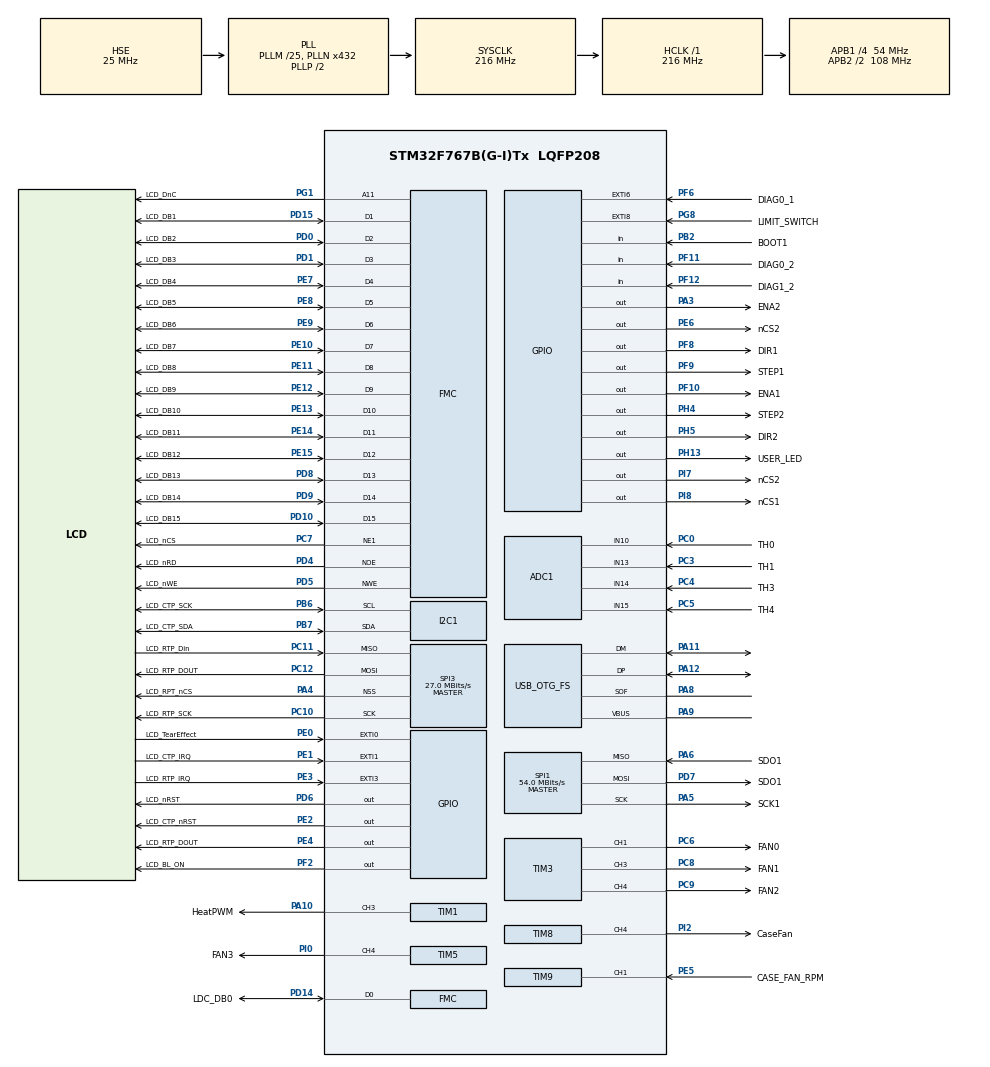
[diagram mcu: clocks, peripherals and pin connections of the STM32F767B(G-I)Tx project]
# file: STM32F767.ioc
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PD7.Mode=Full_Duplex_Master
SH.FMC_D7_DA7.0=FMC_D7,16b-d1
VP_TIM5_VS_ClockSourceINT.Mode=Internal
SPI3.Direction=SPI_DIRECTION_2LINES
SPI3.VirtualType=VM_MASTER
SPI1.VirtualType=VM_MASTER
VP_ADC1_TempSens_Input.Mode=IN-TempSens
PG8.Signal=GPXTI8
PC12.Signal=SPI3_MOSI
PC6.GPIO_Label=FAN0
VP_RTC_VS_RTC_Activate.Mode=RTC_Enabled
PA6.GPIO_Label=SDO1
PB6.GPIO_Label=LCD_CTP_SCK
TIM8.Channel-PWM\ Generation4\ CH4=TIM_CHANNEL_4
SH.FMC_D5_DA5.0=FMC_D5,16b-d1
PD6.GPIO_Label=LCD_nRST
TIM3.Channel-PWM\ Generation4\ CH4=TIM_CHANNEL_4
PE6.GPIO_Label=nCS2
PF6.GPIO_Label=DIAG0_1
SH.FMC_NWE.0=FMC_NWE,Lcd1
RCC.SYSCLKSource=RCC_SYSCLKSOURCE_PLLCLK
SH.FMC_D9_DA9.0=FMC_D9,16b-d1
FREERTOS.configENABLE_FPU=1
PH5.Signal=GPIO_Output
PA4.Mode=NSS_Signal_Hard_Output
NVIC.DMA2D_IRQn=true\:5\:0\:false\:false\:true\:true\:true\:true
SPI1.Direction=SPI_DIRECTION_2LINES
SPI3.VirtualNSS=VM_NSSHARD
SH.FMC_D11_DA11.0=FMC_D11,16b-d1
PD4.Signal=FMC_NOE
RCC.APB2TimFreq_Value=216000000
PB6.Signal=I2C1_SCL
PC7.Signal=FMC_NE1
PH1/OSC_OUT.Signal=RCC_OSC_OUT
PB6.Mode=I2C
SPI1.CalculateBaudRate=54.0 MBits/s
PC3.Signal=ADCx_IN13
PD0.Signal=FMC_D2_DA2
PD8.Signal=FMC_D13_DA13
PE5.Signal=S_TIM9_CH1
PE1.Signal=GPXTI1
FREERTOS.configMINIMAL_STACK_SIZE=2048
PF10.GPIO_Label=ENA1
PB2.Signal=GPIO_Input
SH.ADCx_IN15.0=ADC1_IN15,IN15
PD1.GPIO_Label=LCD_DB3
PF12.GPIO_Label=DIAG1_2
FMC.DataSetupTime1=8
PC4.GPIO_Label=TH3
PE9.Signal=FMC_D6_DA6
PF6.Stacked=true
PE4.GPIO_Label=LCD_RTP_DOUT
PE2.Signal=GPIO_Output
PA8.Signal=USB_OTG_FS_SOF
SH.FMC_D1_DA1.0=FMC_D1,16b-d1
PE10.Signal=FMC_D7_DA7
VP_TIM1_VS_ClockSourceINT.Mode=Internal
ADC1.SamplingTime-0\#ChannelRegularConversion=ADC_SAMPLETIME_3CYCLES
Mcu.Package=LQFP208
FREERTOS.configUSE_NEWLIB_REENTRANT=1
SH.S_TIM8_CH4.0=TIM8_CH4,PWM Generation4 CH4
NVIC.TimeBase=TIM7_IRQn
SPI3.Mode=SPI_MODE_MASTER
SH.ADCx_IN14.0=ADC1_IN14,IN14
STMicroelectronics.X-CUBE-TOUCHGFX.4.16.1.ApplicationCcGraphicsJjApplication=TouchGFXOoGenerator
NVIC.TimeBaseIP=TIM7
PA10.Signal=S_TIM1_CH3
VP_RTC_VS_RTC_Calendar.Mode=RTC_Calendar
PE12.GPIO_Label=LCD_DB9
PC11.Mode=Full_Duplex_Master
RCC.APB2CLKDivider=RCC_HCLK_DIV2
RCC.APB1TimFreq_Value=108000000
VP_DMA2D_VS_DMA2D.Mode=DMA2D_Activate
PE10.GPIO_Label=LCD_DB7
PA4.GPIO_Label=LCD_RPT_nCS
PD15.Signal=FMC_D1_DA1
SH.FMC_D3_DA3.0=FMC_D3,16b-d1
STMicroelectronics.X-CUBE-TOUCHGFX.4.16.1.tgfx_block_size=16000
PA5.Mode=Full_Duplex_Master
VP_STMicroelectronics.X-CUBE-TOUCHGFX_VS_GraphicsJjApplication_4.16.1.Mode=GraphicsJjApplication
VP_TIM9_VS_ControllerModeClock.Mode=Clock Mode
STMicroelectronics.X-CUBE-TOUCHGFX.4.16.1.tgfx_custom_height=480
FREERTOS.Tasks01=defaultTask,24,2048,StartDefaultTask,Default,NULL,Dynamic,NULL,NULL
ADC1.Rank-0\#ChannelRegularConversion=1
PH13.Signal=GPIO_Output
PD9.GPIO_Label=LCD_DB14
FREERTOS.INCLUDE_xTaskGetCurrentTaskHandle=1
SH.FMC_D10_DA10.0=FMC_D10,16b-d1
PC6.Signal=S_TIM3_CH1
PD7.Signal=SPI1_MOSI
PD1.Signal=FMC_D3_DA3
VP_TIM8_VS_ClockSourceITR.Mode=TriggerSource_ITR0
PC0.Signal=ADCx_IN10
RCC.APB1CLKDivider=RCC_HCLK_DIV4
SH.FMC_NOE.0=FMC_NOE,Lcd1
PF8.GPIO_Label=DIR1
PD10.Signal=FMC_D15_DA15
TIM3.Channel-PWM\ Generation3\ CH3=TIM_CHANNEL_3
FMC.AddressSetupTime1=6
PI8.GPIO_Label=nCS1
USB_DEVICE.PRODUCT_STRING_CDC_FS=KTI-STM32 Virtual ComPort
SH.FMC_D15_DA15.0=FMC_D15,16b-d1
PE8.GPIO_Label=LCD_DB5
PA9.Signal=USB_OTG_FS_VBUS
I2C1.Timing=0x20404768
PE9.GPIO_Label=LCD_DB6
PA5.Signal=SPI1_SCK
PC12.Mode=Full_Duplex_Master
PE1.GPIO_Label=LCD_CTP_IRQ
PI7.Signal=GPIO_Output
PE14.Signal=FMC_D11_DA11
PE15.Signal=FMC_D12_DA12
PE8.Signal=FMC_D5_DA5
SPI1.Mode=SPI_MODE_MASTER
PI2.Signal=S_TIM8_CH4
SH.S_TIM9_CH1.0=TIM9_CH1,TriggerSource_TI1ED
PA13.Mode=Serial_Wire
VP_TIM9_VS_CH1.Mode=Input_Capture1_from_TRC
PC7.GPIO_Label=LCD_nCS
PA4.Signal=SPI3_NSS
ADC1.master=1
PE13.GPIO_Label=LCD_DB10
PA5.GPIO_Label=SCK1
PE5.GPIO_Label=CASE_FAN_RPM
PC12.GPIO_Label=LCD_RTP_DOUT
PA11.Signal=USB_OTG_FS_DM
ProjectManager.HeapSize=0x10000
PF9.Signal=GPIO_Output
NVIC.PriorityGroup=NVIC_PRIORITYGROUP_4
PE3.Signal=GPXTI3
PC3.GPIO_Label=TH1
PA8.Mode=Activate_SOF_FS
TIM1.Channel-PWM\ Generation3\ CH3=TIM_CHANNEL_3
VP_TIM8_VS_ControllerModeReset.Mode=Reset Mode
Mcu.Family=STM32F7
PA6.Mode=Full_Duplex_Master
USB_DEVICE.CLASS_NAME_FS=CDC
RCC.CortexFreq_Value=216000000
TIM5.Channel-Output\ Compare4\ CH4=TIM_CHANNEL_4
SH.FMC_D14_DA14.0=FMC_D14,16b-d1
PE11.GPIO_Label=LCD_DB8
STMicroelectronics.X-CUBE-TOUCHGFX.4.16.1.tgfx_buffering_strategy=Partial
PC10.Signal=SPI3_SCK
SH.FMC_D6_DA6.0=FMC_D6,16b-d1
PC0.GPIO_Label=TH0
PD0.GPIO_Label=LCD_DB2
PA11.Mode=Device_Only
STMicroelectronics.X-CUBE-ALGOBUILD.1.2.0.LibraryCcMotionOoLibrariesJjMotionOoLibraries=true
USB_DEVICE.VirtualMode-CDC_FS=Cdc
PH5.GPIO_Label=DIR2
SH.FMC_A11.0=FMC_A11,A11_1
ProjectManager.StackSize=0x1000
VP_FREERTOS_VS_CMSIS_V2.Mode=CMSIS_V2
TIM9.Channel-Input_Capture1_from_TRC=TIM_CHANNEL_1
PA12.Signal=USB_OTG_FS_DP
VP_STMicroelectronics.X-CUBE-ALGOBUILD_VS_MotionOoLibrariesJjLibrary_1.2.0_1.2.0.Mode=MotionOoLibrariesJjLibrary
PH0/OSC_IN.Mode=HSE-External-Clock-Source
RCC.HCLKFreq_Value=216000000
PF11.GPIO_Label=DIAG0_2
PF12.Signal=GPIO_Input
RCC.AHBFreq_Value=216000000
TIM3.Channel-PWM\ Generation1\ CH1=TIM_CHANNEL_1
ADC1.Channel-0\#ChannelRegularConversion=ADC_CHANNEL_TEMPSENSOR
RCC.HSE_VALUE=25000000
STMicroelectronics.X-CUBE-TOUCHGFX.4.16.1.tgfx_number_of_blocks=4
SH.FMC_D8_DA8.0=FMC_D8,16b-d1
PI8.Signal=GPIO_Output
SH.FMC_D2_DA2.0=FMC_D2,16b-d1
FMC.BusTurnAroundDuration1=6
PE13.Signal=FMC_D10_DA10
PA14.Mode=Serial_Wire
PI0.Signal=S_TIM5_CH4
PF11.Signal=GPIO_Input
PC11.GPIO_Label=LCD_RTP_Din
PA10.GPIO_Label=HeatPWM
PB7.Signal=I2C1_SDA
SH.S_TIM3_CH1.0=TIM3_CH1,PWM Generation1 CH1
DMA2D.ColorMode=DMA2D_OUTPUT_RGB565
PH1/OSC_OUT.Mode=HSE-External-Clock-Source
PE4.Signal=GPIO_Output
FREERTOS.configTOTAL_HEAP_SIZE=98304
PD7.GPIO_Label=SDO1
PB7.GPIO_Label=LCD_CTP_SDA
PA6.Signal=SPI1_MISO
SH.FMC_D0_DA0.0=FMC_D0,16b-d1
PD5.GPIO_Label=LCD_nWE
NVIC.OTG_FS_IRQn=true\:5\:0\:false\:false\:true\:true\:false\:true
USB_OTG_FS.VirtualMode=Device_Only
PF8.Signal=GPIO_Output
SH.FMC_D4_DA4.0=FMC_D4,16b-d1
PI0.GPIO_Label=FAN3
PE0.GPIO_Label=LCD_TearEffect
PC5.Signal=ADCx_IN15
PE7.Signal=FMC_D4_DA4
PI2.GPIO_Label=CaseFan
FREERTOS.configMAX_TASK_NAME_LEN=32
PD6.Signal=GPIO_Output
PE2.GPIO_Label=LCD_CTP_nRST
NVIC.TIM7_IRQn=true\:0\:0\:false\:false\:true\:false\:false\:true
VP_TIM3_VS_ClockSourceINT.Mode=Internal
PA3.Signal=GPIO_Output
SH.ADCx_IN13.0=ADC1_IN13,IN13
PD15.GPIO_Label=LCD_DB1
PC10.GPIO_Label=LCD_RTP_SCK
SH.SharedStack_PF6.0=GPIO_EXTI6
PC9.GPIO_Label=FAN2
USB_DEVICE.VirtualModeFS=Cdc_FS
PG1.Signal=FMC_A11
PC11.Signal=SPI3_MISO
VP_SYS_VS_tim7.Mode=TIM7
PC8.Signal=S_TIM3_CH3
PC4.Signal=ADCx_IN14
PC10.Mode=Full_Duplex_Master
PE14.GPIO_Label=LCD_DB11
PD9.Signal=FMC_D14_DA14
PD5.Signal=FMC_NWE
SH.S_TIM3_CH3.0=TIM3_CH3,PWM Generation3 CH3
PD8.GPIO_Label=LCD_DB13
STMicroelectronics.X-CUBE-TOUCHGFX.4.16.1.tgfx_custom_width=800
PH13.GPIO_Label=USER_LED
PG8.GPIO_Label=LIMIT_SWITCH
PC8.GPIO_Label=FAN1
PA13.Signal=SYS_JTMS-SWDIO
PA9.Mode=Activate_VBUS
PE15.GPIO_Label=LCD_DB12
PH4.Signal=GPIO_Output
PF6.Signal=SharedStack_PF6
ProjectManager.TargetToolchain=STM32CubeIDE
SH.FMC_D13_DA13.0=FMC_D13,16b-d1
VP_USB_DEVICE_VS_USB_DEVICE_CDC_FS.Mode=CDC_FS
PF2.Signal=GPIO_Output
RCC.USBFreq_Value=48000000
PF9.GPIO_Label=STEP1
PD10.GPIO_Label=LCD_DB15
PE11.Signal=FMC_D8_DA8
RCC.LSE_VALUE=32768
board=custom
RCC.VCOOutputFreq_Value=432000000
PG1.GPIO_Label=LCD_DnC
PH4.GPIO_Label=STEP2
PH0/OSC_IN.Signal=RCC_OSC_IN
RCC.APB2Freq_Value=108000000
SPI3.CalculateBaudRate=27.0 MBits/s
VP_TIM2_VS_ClockSourceINT.Mode=Internal
PD4.GPIO_Label=LCD_nRD
PF10.Signal=GPIO_Output
SH.FMC_D12_DA12.0=FMC_D12,16b-d1
PI7.GPIO_Label=nCS2
SH.S_TIM5_CH4.0=TIM5_CH4,Output Compare4 CH4
PD14.GPIO_Label=LDC_DB0
PE6.Signal=GPIO_Output
Mcu.Name=STM32F767B(G-I)Tx
PE0.Signal=GPXTI0
PE7.GPIO_Label=LCD_DB4
PE12.Signal=FMC_D9_DA9
PD14.Signal=FMC_D0_DA0
NVIC.EXTI0_IRQn=true\:5\:0\:false\:false\:true\:true\:true\:true
RCC.SYSCLKFreq_VALUE=216000000
PA12.Mode=Device_Only
PC5.GPIO_Label=TH4
PB7.Mode=I2C
PA14.Signal=SYS_JTCK-SWCLK
PB2.GPIO_Label=BOOT1
SH.ADCx_IN10.0=ADC1_IN10,IN10
SH.S_TIM1_CH3.0=TIM1_CH3,PWM Generation3 CH3
RCC.HSI_VALUE=16000000
RCC.PLLQ=9
ADC1.NbrOfConversionFlag=1
RCC.PLLM=25
RCC.PLLN=432
PE3.GPIO_Label=LCD_RTP_IRQ
PC9.Signal=S_TIM3_CH4
PC7.Mode=NorPsramChipSelect1_1
RCC.APB1Freq_Value=54000000
VP_CRC_VS_CRC.Mode=CRC_Activate
PA3.GPIO_Label=ENA2
SH.S_TIM3_CH4.0=TIM3_CH4,PWM Generation4 CH4
PF2.GPIO_Label=LCD_BL_ON

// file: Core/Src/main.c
/* USER CODE BEGIN Header */
/**
 ******************************************************************************
 * @file           : main.c
 * @brief          : Main program body
 ******************************************************************************
 * @attention
 *
 * <h2><center>&copy; Copyright (c) 2021 STMicroelectronics.
 * All rights reserved.</center></h2>
 *
 * This software component is licensed by ST under BSD 3-Clause license,
 * the "License"; You may not use this file except in compliance with the
 * License. You may obtain a copy of the License at:
 *                        opensource.org/licenses/BSD-3-Clause
 *
 ******************************************************************************
 */
/* USER CODE END Header */
#include "main.h"
#include "cmsis_os.h"
#include "adc.h"
#include "crc.h"
#include "dma2d.h"
#include "i2c.h"
#include "rtc.h"
#include "spi.h"
#include "tim.h"
#include "usb_device.h"
#include "gpio.h"
#include "fmc.h"
#include "app_touchgfx.h"

/* USER CODE BEGIN PV */
osThreadId_t defaultTaskHandle;
const osThreadAttr_t defaultTask_attributes = { .name = "defaultTask",
		.stack_size = 2048 * 4, .priority = (osPriority_t) osPriorityNormal, };
/* USER CODE BEGIN PV */
const osThreadAttr_t touchGFX_Task_attributes = { .name = "TouchGFX",
		.priority = (osPriority_t) osPriorityNormal, .stack_size = 1024 * 32 };
__NO_RETURN void TouchGFX_Task(void *argument);

osThreadId_t MainTskHandle;
osThreadId_t MotorTskHandle;
osThreadId_t HeaterTskHandle;
osThreadId_t GfxTskHandle;
osThreadId_t UsbTskHandle;

osMessageQueueId_t GfxQHandle;
osMessageQueueId_t MotorQHandle;
osMessageQueueId_t HeaterQHandle;
osMessageQueueId_t MainQHandle;
osMessageQueueId_t UsbQHandle;
osThreadId_t MainTskHandle;

/* USER CODE END PV */

void SystemClock_Config(void);
void MX_FREERTOS_Init(void);

int main(void) {

	/* MCU Configuration--------------------------------------------------------*/

	/* Reset of all peripherals, Initializes the Flash interface and the Systick. */
	HAL_Init();

	/* Configure the system clock */
	SystemClock_Config();

	/* Initialize all configured peripherals */
	MX_GPIO_Init();
	MX_CRC_Init();
	MX_DMA2D_Init();
	MX_FMC_Init();
	MX_I2C1_Init();
	MX_SPI1_Init();
	MX_RTC_Init();
	MX_TIM2_Init();
	MX_TIM3_Init();
	MX_SPI3_Init();
	MX_TIM9_Init();
	MX_ADC1_Init();
	MX_TIM5_Init();
	MX_TIM8_Init();
	MX_TIM1_Init();
	MX_TouchGFX_Init();
	/* USER CODE BEGIN 2 */
	/* USER CODE BEGIN RTOS_QUEUES */
	/* add queues, ... */

	MotorQHandle = osMessageQueueNew(MSG_COUNT, sizeof(T_MSG), NULL);
	HeaterQHandle = osMessageQueueNew(MSG_COUNT, sizeof(T_MSG), NULL);
	GfxQHandle = osMessageQueueNew(MSG_COUNT, sizeof(T_MSG), NULL);
	UsbQHandle = osMessageQueueNew(MSG_COUNT, sizeof(T_MSG), NULL);
	MainQHandle = osMessageQueueNew(MSG_COUNT, sizeof(T_MSG), NULL);
	/* USER CODE END RTOS_QUEUES */

	/* Create the thread(s) */
	/* USER CODE BEGIN RTOS_THREADS */
	/* add threads, ... */

	MainTskHandle = osThreadNew(StartTaskMain, NULL, &defaultTask_attributes); //	osPriorityNormal, 0, 2048);
	MotorTskHandle = osThreadNew(StartTaskMotor, NULL, &defaultTask_attributes);
	HeaterTskHandle = osThreadNew(StartTaskHeater, NULL, &defaultTask_attributes);
	UsbTskHandle = osThreadNew(StartTaskUSB, NULL, &defaultTask_attributes);
	GfxTskHandle = osThreadNew(TouchGFX_Task, NULL, &touchGFX_Task_attributes);

	/* USER CODE END 2 */

	/* Init scheduler */
	osKernelInitialize(); /* Call init function for freertos objects (in freertos.c) */
	MX_FREERTOS_Init();
	/* Start scheduler */
	osKernelStart();

	/* We should never get here as control is now taken by the scheduler */
	/* Infinite loop */
	while (1) {

	}
}

void SystemClock_Config(void) {
	RCC_OscInitTypeDef RCC_OscInitStruct = { 0 };
	RCC_ClkInitTypeDef RCC_ClkInitStruct = { 0 };
	RCC_PeriphCLKInitTypeDef PeriphClkInitStruct = { 0 };

	/** Configure the main internal regulator output voltage
	 */
	__HAL_RCC_PWR_CLK_ENABLE();
	__HAL_PWR_VOLTAGESCALING_CONFIG(PWR_REGULATOR_VOLTAGE_SCALE1);
	/** Initializes the RCC Oscillators according to the specified parameters
	 * in the RCC_OscInitTypeDef structure.
	 */
	RCC_OscInitStruct.OscillatorType = RCC_OSCILLATORTYPE_LSI
			| RCC_OSCILLATORTYPE_HSE;
	RCC_OscInitStruct.HSEState = RCC_HSE_BYPASS;
	RCC_OscInitStruct.LSIState = RCC_LSI_ON;
	RCC_OscInitStruct.PLL.PLLState = RCC_PLL_ON;
	RCC_OscInitStruct.PLL.PLLSource = RCC_PLLSOURCE_HSE;
	RCC_OscInitStruct.PLL.PLLM = 25;
	RCC_OscInitStruct.PLL.PLLN = 432;
	RCC_OscInitStruct.PLL.PLLP = RCC_PLLP_DIV2;
	RCC_OscInitStruct.PLL.PLLQ = 9;
	if (HAL_RCC_OscConfig(&RCC_OscInitStruct) != HAL_OK) {
		Error_Handler();
	}
	/** Activate the Over-Drive mode
	 */
	if (HAL_PWREx_EnableOverDrive() != HAL_OK) {
		Error_Handler();
	}
	/** Initializes the CPU, AHB and APB buses clocks
	 */
	RCC_ClkInitStruct.ClockType = RCC_CLOCKTYPE_HCLK | RCC_CLOCKTYPE_SYSCLK
			| RCC_CLOCKTYPE_PCLK1 | RCC_CLOCKTYPE_PCLK2;
	RCC_ClkInitStruct.SYSCLKSource = RCC_SYSCLKSOURCE_PLLCLK;
	RCC_ClkInitStruct.AHBCLKDivider = RCC_SYSCLK_DIV1;
	RCC_ClkInitStruct.APB1CLKDivider = RCC_HCLK_DIV4;
	RCC_ClkInitStruct.APB2CLKDivider = RCC_HCLK_DIV2;

	if (HAL_RCC_ClockConfig(&RCC_ClkInitStruct, FLASH_LATENCY_7) != HAL_OK) {
		Error_Handler();
	}
	PeriphClkInitStruct.PeriphClockSelection = RCC_PERIPHCLK_RTC
			| RCC_PERIPHCLK_I2C1 | RCC_PERIPHCLK_CLK48;
	PeriphClkInitStruct.RTCClockSelection = RCC_RTCCLKSOURCE_LSI;
	PeriphClkInitStruct.I2c1ClockSelection = RCC_I2C1CLKSOURCE_PCLK1;
	PeriphClkInitStruct.Clk48ClockSelection = RCC_CLK48SOURCE_PLL;
	if (HAL_RCCEx_PeriphCLKConfig(&PeriphClkInitStruct) != HAL_OK) {
		Error_Handler();
	}
}

void HAL_TIM_PeriodElapsedCallback(TIM_HandleTypeDef *htim) {
	if (htim->Instance == TIM7) {
		HAL_IncTick();
	}
}

void Error_Handler(void) {
	__disable_irq();
	while (1) {
	}
}

/************************ (C) COPYRIGHT STMicroelectronics *****END OF FILE****/

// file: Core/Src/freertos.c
/* USER CODE BEGIN Header */
/**
  ******************************************************************************
  * File Name          : freertos.c
  * Description        : Code for freertos applications
  ******************************************************************************
  * @attention
  *
  * <h2><center>&copy; Copyright (c) 2021 STMicroelectronics.
  * All rights reserved.</center></h2>
  *
  * This software component is licensed by ST under Ultimate Liberty license
  * SLA0044, the "License"; You may not use this file except in compliance with
  * the License. You may obtain a copy of the License at:
  *                             www.st.com/SLA0044
  *
  ******************************************************************************
  */
/* USER CODE END Header */

#include "FreeRTOS.h"
#include "task.h"
#include "main.h"
#include "cmsis_os.h"

/* Definitions for defaultTask */
osThreadId_t defaultTaskHandle;
const osThreadAttr_t defaultTask_attributes = {
  .name = "defaultTask",
  .stack_size = 2048 * 4,
  .priority = (osPriority_t) osPriorityNormal,
};

void StartDefaultTask(void *argument);

extern void MX_USB_DEVICE_Init(void);
void MX_FREERTOS_Init(void); /* (MISRA C 2004 rule 8.1) */

void MX_FREERTOS_Init(void) {

  /* Create the thread(s) */
  /* creation of defaultTask */
  defaultTaskHandle = osThreadNew(StartDefaultTask, NULL, &defaultTask_attributes);

}

void StartDefaultTask(void *argument)
{
  /* init code for USB_DEVICE */
  MX_USB_DEVICE_Init();
  for(;;)
  {
    osDelay(1);
  }
}

/************************ (C) COPYRIGHT STMicroelectronics *****END OF FILE****/
